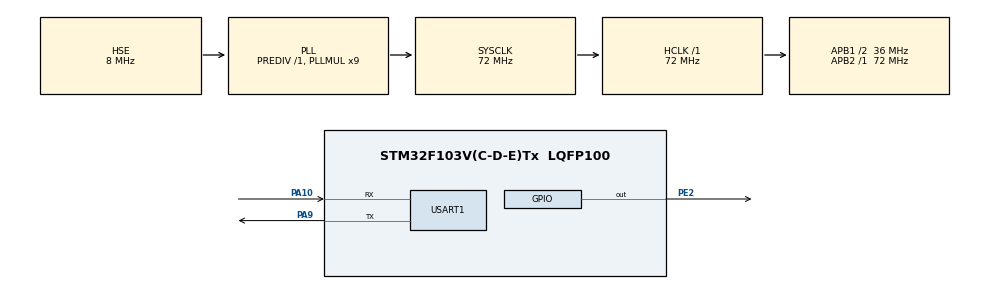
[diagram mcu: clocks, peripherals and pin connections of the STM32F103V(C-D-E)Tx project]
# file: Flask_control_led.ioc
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Mcu.Family=STM32F1
Mcu.Name=STM32F103V(C-D-E)Tx
Mcu.Package=LQFP100
NVIC.PriorityGroup=NVIC_PRIORITYGROUP_4
NVIC.USART1_IRQn=true\:0\:0\:false\:false\:true\:true\:true
OSC_IN.Mode=HSE-External-Oscillator
OSC_IN.Signal=RCC_OSC_IN
OSC_OUT.Mode=HSE-External-Oscillator
OSC_OUT.Signal=RCC_OSC_OUT
PA10.Mode=Asynchronous
PA10.Signal=USART1_RX
PA9.Mode=Asynchronous
PA9.Signal=USART1_TX
PE2.Signal=GPIO_Output
ProjectManager.HeapSize=0x200
ProjectManager.StackSize=0x400
ProjectManager.TargetToolchain=STM32CubeIDE
RCC.AHBFreq_Value=72000000
RCC.APB1CLKDivider=RCC_HCLK_DIV2
RCC.APB1Freq_Value=36000000
RCC.APB1TimFreq_Value=72000000
RCC.APB2Freq_Value=72000000
RCC.APB2TimFreq_Value=72000000
RCC.HCLKFreq_Value=72000000
RCC.PLLMUL=RCC_PLL_MUL9
RCC.PLLSourceVirtual=RCC_PLLSOURCE_HSE
RCC.SYSCLKFreq_VALUE=72000000
RCC.SYSCLKSource=RCC_SYSCLKSOURCE_PLLCLK
RCC.USBFreq_Value=72000000
USART1.VirtualMode=VM_ASYNC
VP_SYS_VS_ND.Mode=No_Debug
board=custom

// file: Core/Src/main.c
/* USER CODE BEGIN Header */
/**
  ******************************************************************************
  * @file           : main.c
  * @brief          : Main program body
  ******************************************************************************
  * @attention
  *
  * <h2><center>&copy; Copyright (c) 2021 STMicroelectronics.
  * All rights reserved.</center></h2>
  *
  * This software component is licensed by ST under BSD 3-Clause license,
  * the "License"; You may not use this file except in compliance with the
  * License. You may obtain a copy of the License at:
  *                        opensource.org/licenses/BSD-3-Clause
  *
  ******************************************************************************
  */
/* USER CODE END Header */
#include "main.h"
#include "usart.h"
#include "gpio.h"
#include <stdio.h>
#include <string.h>

// 전역변수로 선언
uint8_t Rx_Data[2];
uint8_t Rx_Buffer[20];
uint8_t USART1_len=0;
uint8_t USART1_rx_end=0;

void HAL_UART_RxCpltCallback(UART_HandleTypeDef *huart)
{
  static uint8_t usart1_chk=0;
  if(huart -> Instance == USART1)
  {
      USART1_rx_end=0;
      switch(usart1_chk)
      {
          case 0:
            if(Rx_Data[0]==0x02)
            {
            	Rx_Buffer[USART1_len]=Rx_Data[0];
                USART1_len++;
                usart1_chk=1;
            }
            else usart1_chk=0;
            break;
          case 1:
            Rx_Buffer[USART1_len]=Rx_Data[0];
            USART1_len++;

            if(Rx_Data[0]==0x03)
            {
              USART1_rx_end=1;
              usart1_chk=0;
            }
            break;
          default:
            usart1_chk=0;
            break;
      }
      HAL_UART_Receive_IT(&huart1, Rx_Data, 1);
  }
}

void SystemClock_Config(void);

int write(int file, unsigned char* p, int len)
{
   HAL_UART_Transmit(&huart1, p, len, 10);
   return len;
}
#ifdef __GNUC__
#define PUTCHAR_PROTOTYPE int __io_putchar(int ch)
#else
#define PUTCHAR_PROTOTYPE int fputc(int ch, FILE *f)  //for printf
#endif
PUTCHAR_PROTOTYPE
{

  HAL_UART_Transmit(&huart1, (uint8_t *)&ch, 1, 0xFFFF);
  return ch;
}
int main(void)
{

  /* MCU Configuration--------------------------------------------------------*/

  /* Reset of all peripherals, Initializes the Flash interface and the Systick. */
  HAL_Init();

  /* Configure the system clock */
  SystemClock_Config();

  /* Initialize all configured peripherals */
  MX_GPIO_Init();
  MX_USART1_UART_Init();
  /* USER CODE BEGIN 2 */

  setvbuf(stdout, NULL, _IONBF, 0);

  //main 함수 while() 문 위에 수신 인터럽트 enable 설정
  HAL_UART_Receive_IT(&huart1, Rx_Data, 1);       // 수신 interrupt Enable 설정
  printf("Program start...  ");

  /* USER CODE END 2 */

  /* Infinite loop */
  while (1)
  {

    /* USER CODE BEGIN 3 */
	// main함수 while문 내에서 주기적으로 USART1_rx_end flag 검사
	if(USART1_rx_end)
	{
	  // 입력 문자열 비교
	  if(!strcmp(Rx_Buffer, "\x02LED ON\x03")) HAL_GPIO_WritePin(GPIOE, GPIO_PIN_2 , GPIO_PIN_SET);
	  else if(!strcmp(Rx_Buffer, "\x02LED OFF\x03")) HAL_GPIO_WritePin(GPIOE, GPIO_PIN_2 , GPIO_PIN_RESET);

	  // 받은 데이터, 전송
	  HAL_UART_Transmit(&huart1, Rx_Buffer, USART1_len, 2);
	  USART1_len=0;
	  USART1_rx_end=0;

	  printf("%s", Rx_Buffer);

	  memset(Rx_Buffer, 0, 20); // 초기화
	 }
  }
  /* USER CODE END 3 */
}

void SystemClock_Config(void)
{
  RCC_OscInitTypeDef RCC_OscInitStruct = {0};
  RCC_ClkInitTypeDef RCC_ClkInitStruct = {0};

  /** Initializes the RCC Oscillators according to the specified parameters
  * in the RCC_OscInitTypeDef structure.
  */
  RCC_OscInitStruct.OscillatorType = RCC_OSCILLATORTYPE_HSE;
  RCC_OscInitStruct.HSEState = RCC_HSE_ON;
  RCC_OscInitStruct.HSEPredivValue = RCC_HSE_PREDIV_DIV1;
  RCC_OscInitStruct.HSIState = RCC_HSI_ON;
  RCC_OscInitStruct.PLL.PLLState = RCC_PLL_ON;
  RCC_OscInitStruct.PLL.PLLSource = RCC_PLLSOURCE_HSE;
  RCC_OscInitStruct.PLL.PLLMUL = RCC_PLL_MUL9;
  if (HAL_RCC_OscConfig(&RCC_OscInitStruct) != HAL_OK)
  {
    Error_Handler();
  }
  /** Initializes the CPU, AHB and APB buses clocks
  */
  RCC_ClkInitStruct.ClockType = RCC_CLOCKTYPE_HCLK|RCC_CLOCKTYPE_SYSCLK
                              |RCC_CLOCKTYPE_PCLK1|RCC_CLOCKTYPE_PCLK2;
  RCC_ClkInitStruct.SYSCLKSource = RCC_SYSCLKSOURCE_PLLCLK;
  RCC_ClkInitStruct.AHBCLKDivider = RCC_SYSCLK_DIV1;
  RCC_ClkInitStruct.APB1CLKDivider = RCC_HCLK_DIV2;
  RCC_ClkInitStruct.APB2CLKDivider = RCC_HCLK_DIV1;

  if (HAL_RCC_ClockConfig(&RCC_ClkInitStruct, FLASH_LATENCY_2) != HAL_OK)
  {
    Error_Handler();
  }
}

void Error_Handler(void)
{
  __disable_irq();
  while (1)
  {
  }
}

/************************ (C) COPYRIGHT STMicroelectronics *****END OF FILE****/
